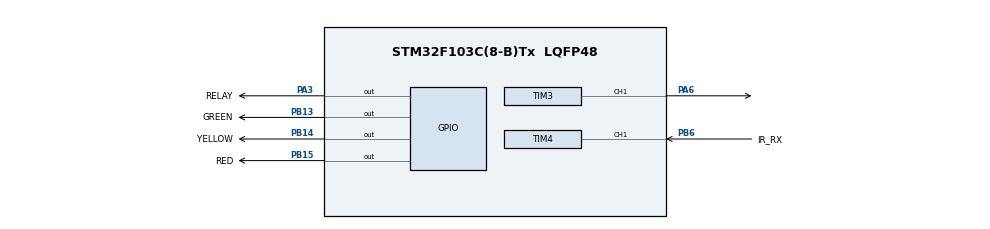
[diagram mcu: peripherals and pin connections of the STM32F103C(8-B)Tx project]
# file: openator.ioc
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IWDG.Prescaler=IWDG_PRESCALER_256
Mcu.Family=STM32F1
Mcu.Name=STM32F103C(8-B)Tx
Mcu.Package=LQFP48
NVIC.PriorityGroup=NVIC_PRIORITYGROUP_4
NVIC.TIM1_CC_IRQn=true\:0\:0\:false\:false\:true\:true\:true\:true
NVIC.TIM1_UP_IRQn=true\:0\:0\:false\:false\:true\:true\:true\:true
NVIC.TIM4_IRQn=true\:0\:0\:false\:false\:true\:true\:true\:true
PA13.Mode=Serial_Wire
PA13.Signal=SYS_JTMS-SWDIO
PA14.Mode=Serial_Wire
PA14.Signal=SYS_JTCK-SWCLK
PA3.GPIO_Label=RELAY
PA3.Signal=GPIO_Output
PA6.Signal=S_TIM3_CH1
PB13.GPIO_Label=GREEN
PB13.Signal=GPIO_Output
PB14.GPIO_Label=YELLOW
PB14.Signal=GPIO_Output
PB15.GPIO_Label=RED
PB15.Signal=GPIO_Output
PB6.GPIO_Label=IR_RX
PB6.Signal=S_TIM4_CH1
PD0-OSC_IN.Mode=HSE-External-Oscillator
PD0-OSC_IN.Signal=RCC_OSC_IN
PD1-OSC_OUT.Mode=HSE-External-Oscillator
PD1-OSC_OUT.Signal=RCC_OSC_OUT
ProjectManager.HeapSize=0x200
ProjectManager.StackSize=0x400
ProjectManager.TargetToolchain=Makefile
RCC.APB1Freq_Value=8000000
RCC.APB2Freq_Value=8000000
RCC.SYSCLKSource=RCC_SYSCLKSOURCE_HSE
SH.S_TIM3_CH1.0=TIM3_CH1,PWM Generation1 CH1
SH.S_TIM4_CH1.0=TIM4_CH1,PWM_Input_1
TIM1.Channel-PWM\ Generation4\ No\ Output=TIM_CHANNEL_4
TIM1.Period=6000-1
TIM1.Prescaler=8000-1
TIM1.Pulse-PWM\ Generation4\ No\ Output=50-1
TIM3.Channel-PWM\ Generation1\ CH1=TIM_CHANNEL_1
TIM3.Period=8-1
TIM3.Prescaler=1000-1
TIM3.Pulse-PWM\ Generation1\ CH1=4-1
TIM4.ICPolarity_1=TIM_INPUTCHANNELPOLARITY_FALLING
TIM4.Period=15000-1
TIM4.Prescaler=8-1
VP_IWDG_VS_IWDG.Mode=IWDG_Activate
VP_TIM1_VS_ClockSourceINT.Mode=Internal
VP_TIM1_VS_no_output4.Mode=PWM Generation4 No Output
board=custom

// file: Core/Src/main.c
/* USER CODE BEGIN Header */
/**
 ******************************************************************************
 * @file           : main.c
 * @brief          : Main program body
 ******************************************************************************
 * @attention
 *
 * Copyright (c) 2024 STMicroelectronics.
 * All rights reserved.
 *
 * This software is licensed under terms that can be found in the LICENSE file
 * in the root directory of this software component.
 * If no LICENSE file comes with this software, it is provided AS-IS.
 *
 ******************************************************************************
 */
/* USER CODE END Header */
#include "main.h"

/* USER CODE BEGIN Includes */
#include "user_main.h"
/* USER CODE END Includes */

IWDG_HandleTypeDef hiwdg;

TIM_HandleTypeDef htim1;
TIM_HandleTypeDef htim3;
TIM_HandleTypeDef htim4;

void SystemClock_Config(void);
static void MX_GPIO_Init(void);
static void MX_TIM4_Init(void);
static void MX_TIM3_Init(void);
static void MX_TIM1_Init(void);
static void MX_IWDG_Init(void);

int main(void)
{

  /* MCU Configuration--------------------------------------------------------*/

  /* Reset of all peripherals, Initializes the Flash interface and the Systick. */
  HAL_Init();

  /* Configure the system clock */
  SystemClock_Config();

  /* Initialize all configured peripherals */
  MX_GPIO_Init();
  MX_TIM4_Init();
  MX_TIM3_Init();
  MX_TIM1_Init();
  MX_IWDG_Init();
  /* USER CODE BEGIN 2 */
  user_main();
  /* USER CODE END 2 */

  /* Infinite loop */
  while (1)
  {

  }
}

void SystemClock_Config(void)
{
  RCC_OscInitTypeDef RCC_OscInitStruct = {0};
  RCC_ClkInitTypeDef RCC_ClkInitStruct = {0};

  /** Initializes the RCC Oscillators according to the specified parameters
  * in the RCC_OscInitTypeDef structure.
  */
  RCC_OscInitStruct.OscillatorType = RCC_OSCILLATORTYPE_LSI|RCC_OSCILLATORTYPE_HSE;
  RCC_OscInitStruct.HSEState = RCC_HSE_ON;
  RCC_OscInitStruct.LSIState = RCC_LSI_ON;
  RCC_OscInitStruct.PLL.PLLState = RCC_PLL_NONE;
  if (HAL_RCC_OscConfig(&RCC_OscInitStruct) != HAL_OK)
  {
    Error_Handler();
  }

  /** Initializes the CPU, AHB and APB buses clocks
  */
  RCC_ClkInitStruct.ClockType = RCC_CLOCKTYPE_HCLK|RCC_CLOCKTYPE_SYSCLK
                              |RCC_CLOCKTYPE_PCLK1|RCC_CLOCKTYPE_PCLK2;
  RCC_ClkInitStruct.SYSCLKSource = RCC_SYSCLKSOURCE_HSE;
  RCC_ClkInitStruct.AHBCLKDivider = RCC_SYSCLK_DIV1;
  RCC_ClkInitStruct.APB1CLKDivider = RCC_HCLK_DIV1;
  RCC_ClkInitStruct.APB2CLKDivider = RCC_HCLK_DIV1;

  if (HAL_RCC_ClockConfig(&RCC_ClkInitStruct, FLASH_LATENCY_0) != HAL_OK)
  {
    Error_Handler();
  }
}

static void MX_IWDG_Init(void)
{

  hiwdg.Instance = IWDG;
  hiwdg.Init.Prescaler = IWDG_PRESCALER_256;
  hiwdg.Init.Reload = 4095;
  if (HAL_IWDG_Init(&hiwdg) != HAL_OK)
  {
    Error_Handler();
  }

}

static void MX_TIM1_Init(void)
{

  TIM_ClockConfigTypeDef sClockSourceConfig = {0};
  TIM_MasterConfigTypeDef sMasterConfig = {0};
  TIM_OC_InitTypeDef sConfigOC = {0};
  TIM_BreakDeadTimeConfigTypeDef sBreakDeadTimeConfig = {0};

  htim1.Instance = TIM1;
  htim1.Init.Prescaler = 8000-1;
  htim1.Init.CounterMode = TIM_COUNTERMODE_UP;
  htim1.Init.Period = 6000-1;
  htim1.Init.ClockDivision = TIM_CLOCKDIVISION_DIV1;
  htim1.Init.RepetitionCounter = 0;
  htim1.Init.AutoReloadPreload = TIM_AUTORELOAD_PRELOAD_DISABLE;
  if (HAL_TIM_Base_Init(&htim1) != HAL_OK)
  {
    Error_Handler();
  }
  sClockSourceConfig.ClockSource = TIM_CLOCKSOURCE_INTERNAL;
  if (HAL_TIM_ConfigClockSource(&htim1, &sClockSourceConfig) != HAL_OK)
  {
    Error_Handler();
  }
  if (HAL_TIM_PWM_Init(&htim1) != HAL_OK)
  {
    Error_Handler();
  }
  sMasterConfig.MasterOutputTrigger = TIM_TRGO_RESET;
  sMasterConfig.MasterSlaveMode = TIM_MASTERSLAVEMODE_DISABLE;
  if (HAL_TIMEx_MasterConfigSynchronization(&htim1, &sMasterConfig) != HAL_OK)
  {
    Error_Handler();
  }
  sConfigOC.OCMode = TIM_OCMODE_PWM1;
  sConfigOC.Pulse = 50-1;
  sConfigOC.OCPolarity = TIM_OCPOLARITY_HIGH;
  sConfigOC.OCFastMode = TIM_OCFAST_DISABLE;
  sConfigOC.OCIdleState = TIM_OCIDLESTATE_RESET;
  sConfigOC.OCNIdleState = TIM_OCNIDLESTATE_RESET;
  if (HAL_TIM_PWM_ConfigChannel(&htim1, &sConfigOC, TIM_CHANNEL_4) != HAL_OK)
  {
    Error_Handler();
  }
  sBreakDeadTimeConfig.OffStateRunMode = TIM_OSSR_DISABLE;
  sBreakDeadTimeConfig.OffStateIDLEMode = TIM_OSSI_DISABLE;
  sBreakDeadTimeConfig.LockLevel = TIM_LOCKLEVEL_OFF;
  sBreakDeadTimeConfig.DeadTime = 0;
  sBreakDeadTimeConfig.BreakState = TIM_BREAK_DISABLE;
  sBreakDeadTimeConfig.BreakPolarity = TIM_BREAKPOLARITY_HIGH;
  sBreakDeadTimeConfig.AutomaticOutput = TIM_AUTOMATICOUTPUT_DISABLE;
  if (HAL_TIMEx_ConfigBreakDeadTime(&htim1, &sBreakDeadTimeConfig) != HAL_OK)
  {
    Error_Handler();
  }

}

static void MX_TIM3_Init(void)
{

  TIM_MasterConfigTypeDef sMasterConfig = {0};
  TIM_OC_InitTypeDef sConfigOC = {0};

  htim3.Instance = TIM3;
  htim3.Init.Prescaler = 1000-1;
  htim3.Init.CounterMode = TIM_COUNTERMODE_UP;
  htim3.Init.Period = 8-1;
  htim3.Init.ClockDivision = TIM_CLOCKDIVISION_DIV1;
  htim3.Init.AutoReloadPreload = TIM_AUTORELOAD_PRELOAD_DISABLE;
  if (HAL_TIM_PWM_Init(&htim3) != HAL_OK)
  {
    Error_Handler();
  }
  sMasterConfig.MasterOutputTrigger = TIM_TRGO_RESET;
  sMasterConfig.MasterSlaveMode = TIM_MASTERSLAVEMODE_DISABLE;
  if (HAL_TIMEx_MasterConfigSynchronization(&htim3, &sMasterConfig) != HAL_OK)
  {
    Error_Handler();
  }
  sConfigOC.OCMode = TIM_OCMODE_PWM1;
  sConfigOC.Pulse = 4-1;
  sConfigOC.OCPolarity = TIM_OCPOLARITY_HIGH;
  sConfigOC.OCFastMode = TIM_OCFAST_DISABLE;
  if (HAL_TIM_PWM_ConfigChannel(&htim3, &sConfigOC, TIM_CHANNEL_1) != HAL_OK)
  {
    Error_Handler();
  }
  HAL_TIM_MspPostInit(&htim3);

}

static void MX_TIM4_Init(void)
{

  TIM_SlaveConfigTypeDef sSlaveConfig = {0};
  TIM_IC_InitTypeDef sConfigIC = {0};
  TIM_MasterConfigTypeDef sMasterConfig = {0};

  htim4.Instance = TIM4;
  htim4.Init.Prescaler = 8-1;
  htim4.Init.CounterMode = TIM_COUNTERMODE_UP;
  htim4.Init.Period = 15000-1;
  htim4.Init.ClockDivision = TIM_CLOCKDIVISION_DIV1;
  htim4.Init.AutoReloadPreload = TIM_AUTORELOAD_PRELOAD_DISABLE;
  if (HAL_TIM_IC_Init(&htim4) != HAL_OK)
  {
    Error_Handler();
  }
  sSlaveConfig.SlaveMode = TIM_SLAVEMODE_RESET;
  sSlaveConfig.InputTrigger = TIM_TS_TI1FP1;
  sSlaveConfig.TriggerPolarity = TIM_INPUTCHANNELPOLARITY_FALLING;
  sSlaveConfig.TriggerPrescaler = TIM_ICPSC_DIV1;
  sSlaveConfig.TriggerFilter = 0;
  if (HAL_TIM_SlaveConfigSynchro(&htim4, &sSlaveConfig) != HAL_OK)
  {
    Error_Handler();
  }
  sConfigIC.ICPolarity = TIM_INPUTCHANNELPOLARITY_FALLING;
  sConfigIC.ICSelection = TIM_ICSELECTION_DIRECTTI;
  sConfigIC.ICPrescaler = TIM_ICPSC_DIV1;
  sConfigIC.ICFilter = 0;
  if (HAL_TIM_IC_ConfigChannel(&htim4, &sConfigIC, TIM_CHANNEL_1) != HAL_OK)
  {
    Error_Handler();
  }
  sConfigIC.ICPolarity = TIM_INPUTCHANNELPOLARITY_RISING;
  sConfigIC.ICSelection = TIM_ICSELECTION_INDIRECTTI;
  if (HAL_TIM_IC_ConfigChannel(&htim4, &sConfigIC, TIM_CHANNEL_2) != HAL_OK)
  {
    Error_Handler();
  }
  sMasterConfig.MasterOutputTrigger = TIM_TRGO_RESET;
  sMasterConfig.MasterSlaveMode = TIM_MASTERSLAVEMODE_DISABLE;
  if (HAL_TIMEx_MasterConfigSynchronization(&htim4, &sMasterConfig) != HAL_OK)
  {
    Error_Handler();
  }

}

static void MX_GPIO_Init(void)
{
  GPIO_InitTypeDef GPIO_InitStruct = {0};

  /* GPIO Ports Clock Enable */
  __HAL_RCC_GPIOD_CLK_ENABLE();
  __HAL_RCC_GPIOA_CLK_ENABLE();
  __HAL_RCC_GPIOB_CLK_ENABLE();

  /*Configure GPIO pin Output Level */
  HAL_GPIO_WritePin(RELAY_GPIO_Port, RELAY_Pin, GPIO_PIN_RESET);

  /*Configure GPIO pin Output Level */
  HAL_GPIO_WritePin(GPIOB, GREEN_Pin|YELLOW_Pin|RED_Pin, GPIO_PIN_RESET);

  /*Configure GPIO pin : RELAY_Pin */
  GPIO_InitStruct.Pin = RELAY_Pin;
  GPIO_InitStruct.Mode = GPIO_MODE_OUTPUT_PP;
  GPIO_InitStruct.Pull = GPIO_NOPULL;
  GPIO_InitStruct.Speed = GPIO_SPEED_FREQ_LOW;
  HAL_GPIO_Init(RELAY_GPIO_Port, &GPIO_InitStruct);

  /*Configure GPIO pins : GREEN_Pin YELLOW_Pin RED_Pin */
  GPIO_InitStruct.Pin = GREEN_Pin|YELLOW_Pin|RED_Pin;
  GPIO_InitStruct.Mode = GPIO_MODE_OUTPUT_PP;
  GPIO_InitStruct.Pull = GPIO_NOPULL;
  GPIO_InitStruct.Speed = GPIO_SPEED_FREQ_LOW;
  HAL_GPIO_Init(GPIOB, &GPIO_InitStruct);

}

void Error_Handler(void)
{
  /* USER CODE BEGIN Error_Handler_Debug */
  /* User can add his own implementation to report the HAL error return state */
  __disable_irq();
  HAL_GPIO_WritePin(RED_GPIO_Port, RED_Pin, GPIO_PIN_SET);
  while (1)
  {
  }
  /* USER CODE END Error_Handler_Debug */
}
